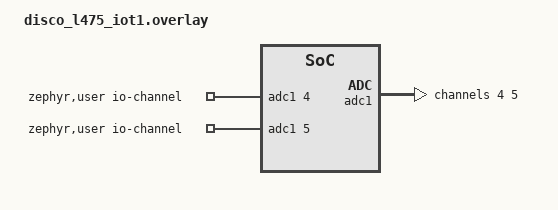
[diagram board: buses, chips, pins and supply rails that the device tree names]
/*
 * Copyright (c) 2022 Kumar Gala <galak@kernel.org>
 *
 * SPDX-License-Identifier: Apache-2.0
 */

tst_dma0: &dma1 {};

/ {
	zephyr,user {
		io-channels = <&adc1 4>, <&adc1 5>;
	};
};

&adc1 {
	dmas = <&dma1 1 0 (STM32_DMA_PERIPH_RX | STM32_DMA_MEM_16BITS | STM32_DMA_PERIPH_16BITS)>;
	dma-names = "dma";
	#address-cells = <1>;
	#size-cells = <0>;
	channel@4 {
		reg = <4>;
		zephyr,gain = "ADC_GAIN_1";
		zephyr,reference = "ADC_REF_INTERNAL";
		zephyr,acquisition-time = <ADC_ACQ_TIME_MAX>;
		zephyr,resolution = <12>;
	};
	channel@5 {
		reg = <5>;
		zephyr,gain = "ADC_GAIN_1";
		zephyr,reference = "ADC_REF_INTERNAL";
		zephyr,acquisition-time = <ADC_ACQ_TIME_MAX>;
		zephyr,resolution = <12>;
	};
};

&dma1 {
	status = "okay";
};

dut: &uart4 {
	dmas = <&dma2 3 2 (STM32_DMA_PERIPH_TX | STM32_DMA_PRIORITY_HIGH)>,
	       <&dma2 5 2 (STM32_DMA_PERIPH_RX | STM32_DMA_PRIORITY_HIGH)>;
	dma-names = "tx", "rx";
};

&dma2 {
	status = "okay";
};
